# EFR32MG22C224F512IM32 register map
Vendor: Silicon Labs; Series: EFR32; File version: C
Registers are 32-bit, read-write, reset 0x0 unless marked. A register's access mark holds for its fields unless they carry their own. Offsets are from the block's base; [hi:lo] are bit positions; {n}, {i} and the like mark numbered series; 'fields as' and 'values as' point back to an identical list.

## SYSCFG_S_CFGNS — SYSCFG_S_CFGNS Registers
Base 0x40078000
Same registers: SYSCFG_NS_CFGNS 0x50078000
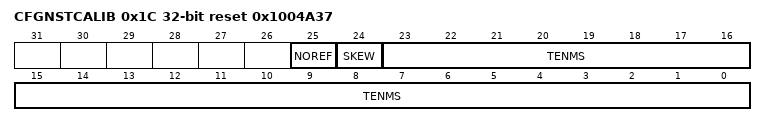
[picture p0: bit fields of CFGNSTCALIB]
0x1C CFGNSTCALIB reset 0x1004A37 — Configure to define the system tick for the M33.
  [25] NOREF — No Reference
    0=REF (Reference clock is implemented); 1=NOREF (Reference clock is not implemented)
  [24] SKEW
  [23:0] TENMS — Ten Milliseconds
0x600 ROOTNSDATA0 — Generic data space for user to pass to root, e.g., address of struct in mem
  [31:0] DATA
0x604 ROOTNSDATA1 — Generic data space for user to pass to root, e.g., address of struct in mem
  [31:0] DATA

## BURAM_S — BURAM_S Registers
Base 0x40080000
Same registers: BURAM_NS 0x50080000
{0x0+4i} RET{i}_REG (i=0..31)
  [31:0] RETREG — Latch based Retention register

## GPCRC_S — GPCRC_S Registers
Base 0x40088000
Same registers: GPCRC_NS 0x50088000
0x00 IPVERSION ro
  [31:0] IPVERSION — IP Version ID
0x04 EN
  [0] EN — CRC Enable
    0=DISABLE (Disable CRC function. Reordering functions are still available. Only BITREVERSE and BYTEREVERSE bits are configurable in this mode.); 1=ENABLE (Writes to INPUTDATA registers will result in CRC operations.)
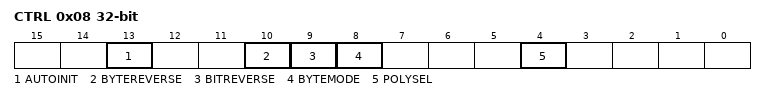
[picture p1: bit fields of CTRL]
0x08 CTRL
  [13] AUTOINIT — Auto Init Enable
  [10] BYTEREVERSE — Byte Reverse Mode
    0=NORMAL (No reverse: B3, B2, B1, B0); 1=REVERSED (Reverse byte order. For 32-bit: B0, B1, B2, B3; For 16-bit: 0, 0, B0, B1)
  [9] BITREVERSE — Byte-level Bit Reverse Enable
    0=NORMAL (No reverse); 1=REVERSED (Reverse bit order in each byte)
  [8] BYTEMODE — Byte Mode Enable
  [4] POLYSEL — Polynomial Select
    0=CRC32 (CRC-32 (0x04C11DB7) polynomial selected); 1=CRC16 (16-bit CRC programmable polynomial selected)
0x0C CMD wo
  [0] INIT — Initialization Enable
0x10 INIT
  [31:0] INIT — CRC Initialization Value
0x14 POLY
  [15:0] POLY — CRC Polynomial Value
0x18 INPUTDATA wo
  [31:0] INPUTDATA — Input Data for 32-bit
0x1C INPUTDATAHWORD wo
  [15:0] INPUTDATAHWORD — Input Data for 16-bit
0x20 INPUTDATABYTE wo
  [7:0] INPUTDATABYTE — Input Data for 8-bit
0x24 DATA ro
  [31:0] DATA — CRC Data Register
0x28 DATAREV ro
  [31:0] DATAREV — Data Reverse Value
0x2C DATABYTEREV ro
  [31:0] DATABYTEREV — Data Byte Reverse Value

## DCDC_S — DCDC_S Registers
Base 0x40094000
Same registers: DCDC_NS 0x50094000
0x00 IPVERSION ro
0x04 EN — Enable
  [0] EN
    0=DISABLE; 1=ENABLE
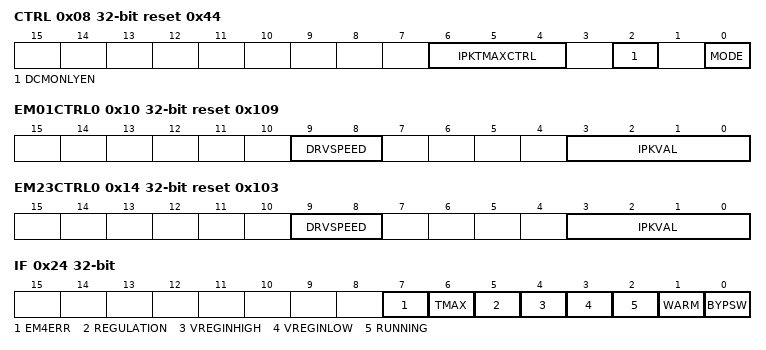
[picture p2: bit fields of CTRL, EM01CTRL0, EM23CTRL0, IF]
0x08 CTRL reset 0x44 — Control
  [6:4] IPKTMAXCTRL — Peak Current Timeout Control
    0=OFF (Ton_max disabled); 1=TMAX_0P35us (0.35us); 2=TMAX_0P63us (0.63us); 3=TMAX_0P91us (0.91us); 4=TMAX_1P19us (1.19us); 5=TMAX_1P47us (1.47us); 6=TMAX_1P75us (1.75us); 7=TMAX_2P03us (2.03us)
  [2] DCMONLYEN — DCDC DCM Only Enable
    0=DUALMODE (Support higher load current at lower battery voltage by working in CCM mode); 1=DCMONLYEN (DCM only mode for normal operation, this is the default setting)
  [0] MODE — DCDC/Bypass Mode Control
    0=BYPASS (DCDC is OFF, bypass switch is enabled); 1=DCDCREGULATION (Request DCDC regulation, bypass switch disabled)
0x10 EM01CTRL0 reset 0x109 — EM01 Configurations
  [9:8] DRVSPEED — EM01 Drive Speed Setting
    0=BEST_EMI (Lowest Efficiency, Lowest EMI.. Small decrease in efficiency from default setting); 1=DEFAULT_SETTING (Default Efficiency, Acceptable EMI level); 2=INTERMEDIATE (Small increase in efficiency from the default setting); 3=BEST_EFFICIENCY (Highest Efficiency, Highest EMI.. Small increase in efficiency from INTERMEDIATE setting)
  [3:0] IPKVAL — EM01 Peak Current Setting
    3=Load36mA (Ipeak = 90mA, IL = 36mA); 4=Load40mA (Ipeak = 100mA, IL = 40mA); 5=Load44mA (Ipeak = 110mA, IL = 44mA); 6=Load48mA (Ipeak = 120mA, IL = 48mA); 7=Load52mA (Ipeak = 130mA, IL = 52mA); 8=Load56mA (Ipeak = 140mA, IL = 56mA); 9=Load60mA (Ipeak = 150mA, IL = 60mA)
0x14 EM23CTRL0 reset 0x103 — EM23 Configurations
  [9:8] DRVSPEED — EM23 Drive Speed Setting
    values as EM01CTRL0.DRVSPEED
  [3:0] IPKVAL — EM23 Peak Current Setting
    3=LOAD5MA (Ipeak = 90mA, IL = 5 mA); 9=LOAD10MA (Ipeak = 150mA, IL = 10 mA)
0x24 IF — Interrupt Flags
  [7] EM4ERR — EM4 Entry Request Error
  [6] TMAX — Ton_max Timeout Reached
  [5] REGULATION — DCDC in regulation
  [4] VREGINHIGH — VREGVDD above threshold
  [3] VREGINLOW — VREGVDD below threshold
  [2] RUNNING — DCDC Running
  [1] WARM — DCDC Warmup Time Done
  [0] BYPSW — Bypass Switch Enabled
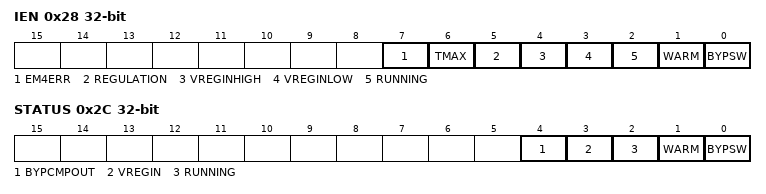
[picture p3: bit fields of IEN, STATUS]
0x28 IEN — Interrupt Enable
  [7] EM4ERR — EM4 Entry Req Interrupt Enable
  [6] TMAX — Ton_max Timeout Interrupt Enable
  [5] REGULATION — DCDC in Regulation Interrupt Enable
  [4] VREGINHIGH — VREGVDD above threshold Interrupt Enable
  [3] VREGINLOW — VREGVDD below threshold Interrupt Enable
  [2] RUNNING — DCDC Running Interrupt Enable
  [1] WARM — DCDC Warmup Time Done Interrupt Enable
  [0] BYPSW — Bypass Switch Enabled Interrupt Enable
0x2C STATUS ro — DCDC Status Register
  [4] BYPCMPOUT — Bypass Comparator Output
  [3] VREGIN — VREGVDD comparator status
  [2] RUNNING — DCDC is running
  [1] WARM — DCDC Warmup Done
  [0] BYPSW — Bypass Switch is currently enabled
0x40 LOCK wo
  [15:0] LOCKKEY — Configuration Lock Key
    0xABCD=UNLOCKKEY (Value to write to unlock)
0x44 LOCKSTATUS ro
  [0] LOCK — Lock Status
    0=UNLOCKED (Unlocked State); 1=LOCKED (LOCKED STATE)
